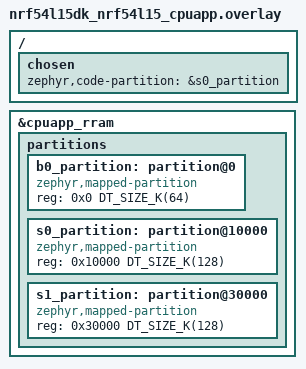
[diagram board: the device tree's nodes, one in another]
/*
 * Copyright (c) 2026 Nordic Semiconductor ASA
 *
 * SPDX-License-Identifier: LicenseRef-Nordic-5-Clause
 */

&cpuapp_rram {
	/delete-node/ partitions;

	partitions {
		ranges;
		#address-cells = <1>;
		#size-cells = <1>;

		b0_partition: partition@0 {
			compatible = "zephyr,mapped-partition";
			reg = <0x0 DT_SIZE_K(64)>;
		};

		s0_partition: partition@10000 {
			compatible = "zephyr,mapped-partition";
			reg = <0x10000 DT_SIZE_K(128)>;
		};

		s1_partition: partition@30000 {
			compatible = "zephyr,mapped-partition";
			reg = <0x30000 DT_SIZE_K(128)>;
		};
	};
};

/ {
	chosen {
		zephyr,code-partition = &s0_partition;
	};
};
